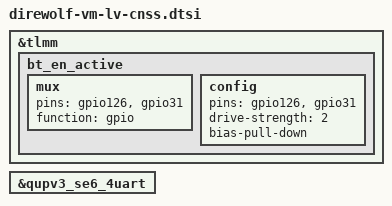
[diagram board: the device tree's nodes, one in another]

&tlmm {
	bt_en_active: bt_en_active {
		mux {
			pins = "gpio126", "gpio31";
			function = "gpio";
		};

		config {
			pins = "gpio126", "gpio31";
			drive-strength = <2>;
			bias-pull-down;
		};
	};
};

&qupv3_se6_4uart {
	status = "ok";
};
